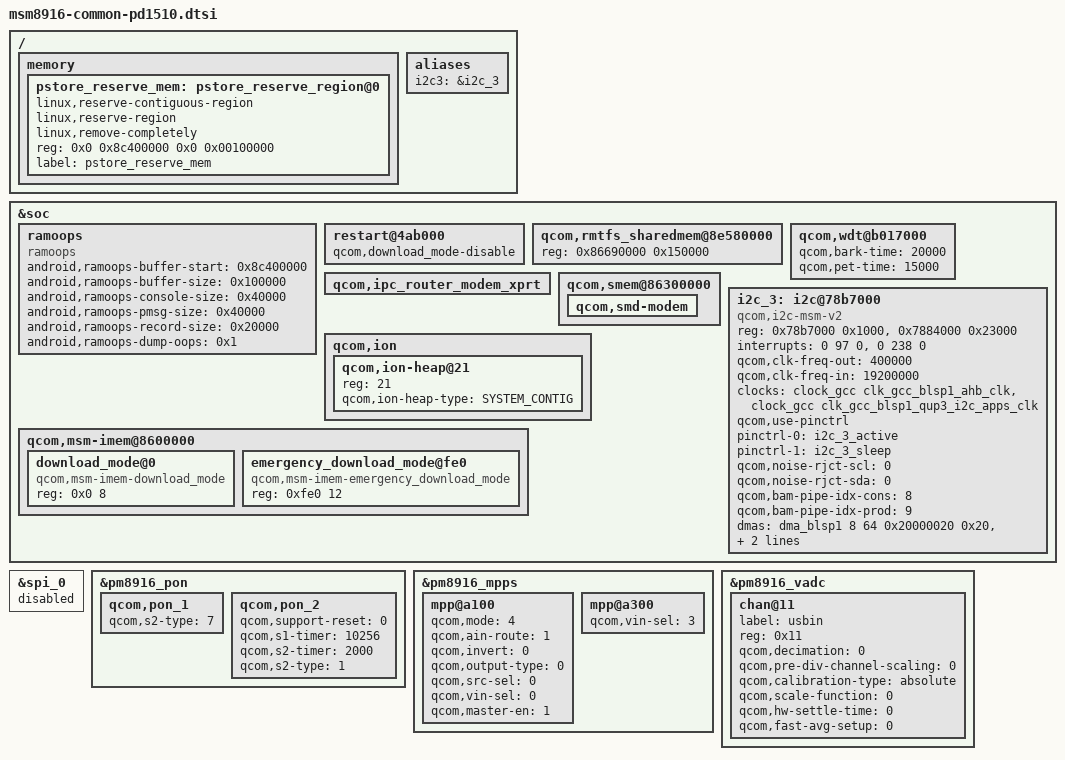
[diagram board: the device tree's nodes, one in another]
/* Copyright (c) 2018, The Linux Foundation. All rights reserved.
*  Copyright (c) 2018, Ketut P. Kumajaya.
*  Copyright (c) 2020, the_shahnawaz_sheikh (sheikhshahnawaz41299).
*
* This program is free software; you can redistribute it and/or modify
* it under the terms of the GNU General Public License version 2 and
* only version 2 as published by the Free Software Foundation.
*
* This program is distributed in the hope that it will be useful,
* but WITHOUT ANY WARRANTY; without even the implied warranty of
* MERCHANTABILITY or FITNESS FOR A PARTICULAR PURPOSE.  See the
* GNU General Public License for more details.
*/
 

/ {
	memory {
		pstore_reserve_mem: pstore_reserve_region@0 {
			linux,reserve-contiguous-region;
			linux,reserve-region;
			linux,remove-completely;
			reg = <0x0 0x8c400000 0x0 0x00100000>;
			label = "pstore_reserve_mem";
		};
	};

	aliases {
		i2c3 = &i2c_3; /* I2C3 controller device */
	};
};

&soc {
	ramoops {
		compatible = "ramoops";
		status = "ok";

		android,ramoops-buffer-start = <0x8c400000>;
		android,ramoops-buffer-size = <0x100000>;
		android,ramoops-console-size = <0x40000>;
		android,ramoops-pmsg-size = <0x40000>;
		android,ramoops-record-size = <0x20000>;
		android,ramoops-dump-oops = <0x1>;
	};

	restart@4ab000 {
		qcom,download_mode-disable;
	};

	qcom,rmtfs_sharedmem@8e580000 {
		reg = <0x86690000 0x150000>;
	};

	qcom,wdt@b017000 {
		qcom,bark-time = <20000>;
		qcom,pet-time = <15000>;
	};

	qcom,ipc_router_modem_xprt {
		/delete-property/ qcom,disable-pil-loading;
	};

	qcom,smem@86300000 {
		qcom,smd-modem {
			/delete-property/ qcom,not-loadable;
		};
	};
	
	i2c_3: i2c@78b7000 { /* BLSP1 QUP3 */
		compatible = "qcom,i2c-msm-v2";
		#address-cells = <1>;
		#size-cells = <0>;
		reg-names = "qup_phys_addr", "bam_phys_addr";
		reg = <0x78b7000 0x1000>,
		      <0x7884000 0x23000>;
		interrupt-names = "qup_irq", "bam_irq";
		interrupts = <0 97 0>, <0 238 0>;
		qcom,clk-freq-out = <400000>;
		qcom,clk-freq-in  = <19200000>;
		clock-names = "iface_clk", "core_clk";
		clocks = <&clock_gcc clk_gcc_blsp1_ahb_clk>,
			<&clock_gcc clk_gcc_blsp1_qup3_i2c_apps_clk>;
		qcom,use-pinctrl;
		pinctrl-names = "i2c_active", "i2c_sleep";
		pinctrl-0 = <&i2c_3_active>;
		pinctrl-1 = <&i2c_3_sleep>;
		qcom,noise-rjct-scl = <0>;
		qcom,noise-rjct-sda = <0>;
		qcom,bam-pipe-idx-cons = <8>;
		qcom,bam-pipe-idx-prod = <9>;
		dmas = <&dma_blsp1 8 64 0x20000020 0x20>,
			<&dma_blsp1 9 32 0x20000020 0x20>;
		dma-names = "tx", "rx";
		qcom,master-id = <86>;
	};
	
	qcom,ion {
		qcom,ion-heap@21 {
			reg = <21>;
			qcom,ion-heap-type = "SYSTEM_CONTIG";
		};
	};

	
	qcom,msm-imem@8600000 {
		download_mode@0 {
			compatible = "qcom,msm-imem-download_mode";
			reg = <0x0 8>;
		};

		emergency_download_mode@fe0 {
			compatible = "qcom,msm-imem-emergency_download_mode";
			reg = <0xfe0 12>;
		};
	};
	
};

&spi_0 { /* BLSP1 QUP3 allocated for i2c_3 */
	status = "disabled";
};

&pm8916_pon {
	qcom,pon_1 {
		qcom,s2-type = <7>;
	};

	qcom,pon_2 {
		qcom,support-reset = <0>;
		qcom,s1-timer = <10256>;
		qcom,s2-timer = <2000>;
		qcom,s2-type = <1>;
	};
};

&pm8916_mpps {
	mpp@a100 { /* MPP 2 */
		/* HR LED */
		status = "ok";
		qcom,mode = <4>;
		qcom,ain-route = <1>;
		qcom,invert = <0>;
		qcom,output-type = <0>;
		qcom,src-sel = <0>;
		qcom,vin-sel = <0>;
		qcom,master-en = <1>;
	};

	mpp@a300 { /* MPP 4 */
		/* Backlight PWM */
		qcom,vin-sel = <3>;
	};
};

&pm8916_vadc {
	chan@11 {
		label = "usbin";
		reg = <0x11>;
		qcom,decimation = <0>;
		qcom,pre-div-channel-scaling = <0>;
		qcom,calibration-type = "absolute";
		qcom,scale-function = <0>;
		qcom,hw-settle-time = <0>;
		qcom,fast-avg-setup = <0>;
	};
};




